# JSTATE_MSP430FR6047 register map
Vendor: Texas Instruments
Peripheral module from a debugger description file (folder msp430).
Registers are 64-bit, read-only, reset 0x0 unless marked. A register's access mark holds for its fields unless they carry their own. Offsets are as the file gives them; lines under a group give offsets from that group; [hi:lo] are bit positions; {n}, {i} and the like mark numbered series; 'fields as' and 'values as' point back to an identical list; <NAME> marks a mode.

## Hidden — JSTATE decoding
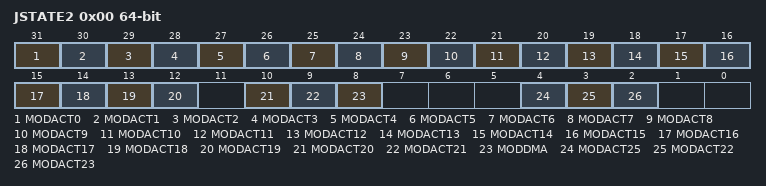
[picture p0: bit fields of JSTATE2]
0x00 JSTATE2 — Digital JTAG State Register
  [31] MODACT0 — FRAM
  [30] MODACT1 — MPY
  [29] MODACT2 — WDT
  [28] MODACT3 — RTC
  [27] MODACT4 — ADC
  [26] MODACT5 — REF
  [25] MODACT6 — COMP
  [24] MODACT7 — AES
  [31-n] MODACT{n} (n=8..11) — eUSCI_A{n-8}
  [19] MODACT12 — eUSCI_B0
  [18] MODACT13 — eUSCI_B1
  [17] MODACT14 — USS_H
  [16] MODACT15 — USS_L
  [15] MODACT16 — TB0
  [14] MODACT17 — TA0
  [13] MODACT18 — TA1
  [12] MODACT19 — TA2
  [10] MODACT20 — TA3
  [9] MODACT21 — TA4
  [8] MODDMA — DMA
  [4] MODACT25 — LCD_C
  [3] MODACT22 — LEA_H
  [2] MODACT23 — LEA_L
